VERSION "synthetic -- generated by libs/dbc_parser/tests/gen_golden.py"

NS_ :

BS_:

BU_ : ECU

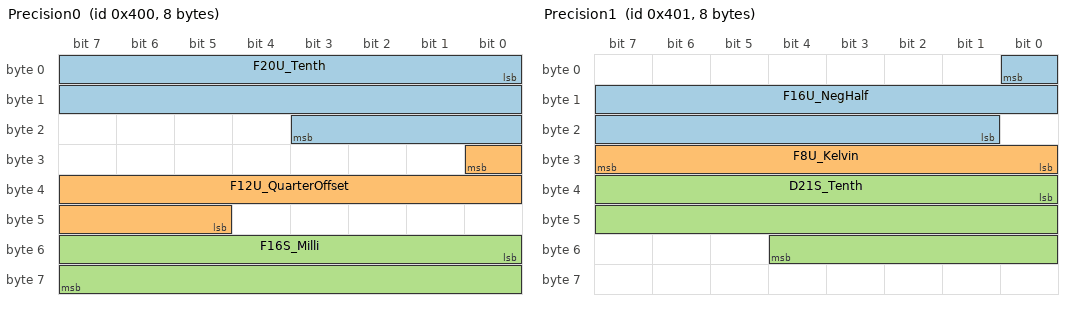
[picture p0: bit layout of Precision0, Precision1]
BO_ 1024 Precision0: 8 ECU
 SG_ F20U_Tenth : 0|20@1+ (0.1,0) [0.0|104857.5] "" ECU
 SG_ F12U_QuarterOffset : 24|12@0+ (0.25,261120) [261120.0|262143.75] "" ECU
 SG_ F16S_Milli : 48|16@1- (0.001,0) [-32.768|32.767] "" ECU

BO_ 1025 Precision1: 8 ECU
 SG_ F16U_NegHalf : 0|16@0+ (-0.5,100) [-32667.5|100.0] "" ECU
 SG_ F8U_Kelvin : 24|8@1+ (0.5,-273.15) [-273.15|-145.64999999999998] "" ECU
 SG_ D21S_Tenth : 32|21@1- (0.1,0) [-104857.6|104857.5] "" ECU

BO_ 1026 Precision2: 8 ECU
 SG_ D20U_HalfHalf : 0|20@0+ (0.5,0.5) [0.5|524288.0] "" ECU
 SG_ D12U_QuarterOffset : 32|12@1+ (0.25,261120.25) [261120.25|262144.0] "" ECU

BO_ 1027 Precision3: 8 ECU
 SG_ D24U_Centi : 0|24@0+ (0.01,0) [0.0|167772.15] "" ECU
 SG_ D32S_CentiOffset : 32|32@1- (0.01,-5) [-21474841.48|21474831.47] "" ECU

BO_ 1028 Precision4: 8 ECU
 SG_ I32U_Times4 : 0|32@0+ (4,0) [0|17179869180] "" ECU

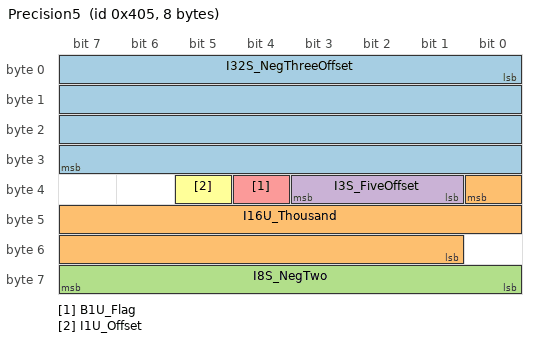
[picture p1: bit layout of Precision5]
BO_ 1029 Precision5: 8 ECU
 SG_ I32S_NegThreeOffset : 0|32@1- (-3,7) [-6442450934|6442450951] "" ECU
 SG_ I16U_Thousand : 32|16@0+ (1000,0) [0|65535000] "" ECU
 SG_ I8S_NegTwo : 56|8@1- (-2,0) [-254|256] "" ECU
 SG_ I3S_FiveOffset : 35|3@0- (5,-1) [-21|14] "" ECU
 SG_ B1U_Flag : 36|1@1+ (1,0) [0|1] "" ECU
 SG_ I1U_Offset : 37|1@0+ (1,5) [5|6] "" ECU

BO_ 1030 Precision6: 8 ECU
 SG_ IeeeScaled : 0|32@1- (0.5,10) [-1073741814.0|1073741833.5] "" ECU

SIG_VALTYPE_ 1030 IeeeScaled : 1;
